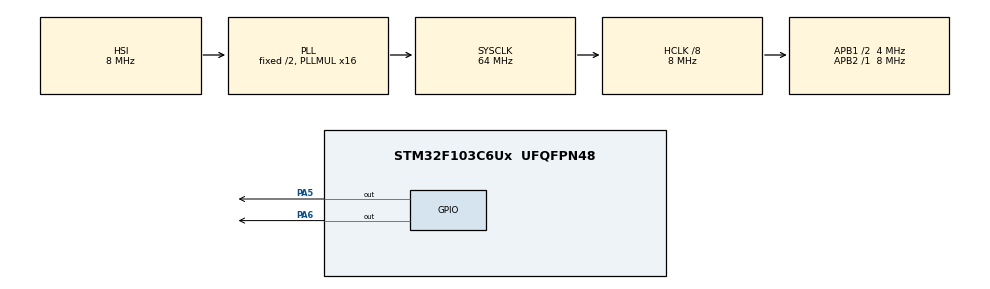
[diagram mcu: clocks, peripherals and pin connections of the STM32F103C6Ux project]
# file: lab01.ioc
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Mcu.Family=STM32F1
Mcu.Name=STM32F103C6Ux
Mcu.Package=UFQFPN48
NVIC.PriorityGroup=NVIC_PRIORITYGROUP_4
PA13.Mode=Serial_Wire
PA13.Signal=SYS_JTMS-SWDIO
PA14.Mode=Serial_Wire
PA14.Signal=SYS_JTCK-SWCLK
PA5.Signal=GPIO_Output
PA6.Signal=GPIO_Output
PC14-OSC32_IN.Mode=LSE-External-Oscillator
PC14-OSC32_IN.Signal=RCC_OSC32_IN
PC15-OSC32_OUT.Mode=LSE-External-Oscillator
PC15-OSC32_OUT.Signal=RCC_OSC32_OUT
PD0-OSC_IN.Mode=HSE-External-Oscillator
PD0-OSC_IN.Signal=RCC_OSC_IN
PD1-OSC_OUT.Mode=HSE-External-Oscillator
PD1-OSC_OUT.Signal=RCC_OSC_OUT
ProjectManager.HeapSize=0x200
ProjectManager.StackSize=0x400
ProjectManager.TargetToolchain=STM32CubeIDE
RCC.AHBCLKDivider=RCC_SYSCLK_DIV8
RCC.AHBFreq_Value=8000000
RCC.APB1CLKDivider=RCC_HCLK_DIV2
RCC.APB1Freq_Value=4000000
RCC.APB1TimFreq_Value=8000000
RCC.APB2Freq_Value=8000000
RCC.APB2TimFreq_Value=8000000
RCC.HCLKFreq_Value=8000000
RCC.PLLMUL=RCC_PLL_MUL16
RCC.SYSCLKFreq_VALUE=64000000
RCC.SYSCLKSource=RCC_SYSCLKSOURCE_PLLCLK
RCC.USBFreq_Value=64000000
board=custom

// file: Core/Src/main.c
/* USER CODE BEGIN Header */
/**
  ******************************************************************************
  * @file           : main.c
  * @brief          : Main program body
  ******************************************************************************
  * @attention
  *
  * Copyright (c) 2024 STMicroelectronics.
  * All rights reserved.
  *
  * This software is licensed under terms that can be found in the LICENSE file
  * in the root directory of this software component.
  * If no LICENSE file comes with this software, it is provided AS-IS.
  *
  ******************************************************************************
  */
/* USER CODE END Header */

#include "main.h"

/* USER CODE BEGIN Includes */
#include <Exercise_01.h>
/* USER CODE END Includes */

void SystemClock_Config(void);
static void MX_GPIO_Init(void);

/* USER CODE BEGIN 0 */
// Định nghĩa thời gian bật/tắt LED
#define RED_LED_ON_TIME 2 // Thời gian bật LED đỏ, đơn vị s
#define RED_LED_OFF_TIME 2 // Thời gian tắt LED đỏ, đơn vị s
#define YELLOW_LED_ON_TIME 2 // Thời gian bật LED vàng, đơn vị s
#define YELLOW_LED_OFF_TIME 2// Thời gian tắt LED vàng, đơn vị s

// Khai báo cấu trúc LED
static led_t red_led = {
    .GPIOx = GPIOA,
    .GPIO_Pin = GPIO_PIN_5,
    .status = LED_OFF,
    .counter = RED_LED_ON_TIME,
    .on_time = RED_LED_ON_TIME,
    .off_time = RED_LED_OFF_TIME
};

static led_t yellow_led = {
    .GPIOx = GPIOA,
    .GPIO_Pin = GPIO_PIN_6,
    .status = LED_ON,
    .counter = YELLOW_LED_OFF_TIME,
    .on_time = YELLOW_LED_ON_TIME,
    .off_time = YELLOW_LED_OFF_TIME
};
/* USER CODE END 0 */

int main(void)
{

  /* MCU Configuration--------------------------------------------------------*/

  /* Reset of all peripherals, Initializes the Flash interface and the Systick. */
  HAL_Init();

  /* Configure the system clock */
  SystemClock_Config();

  /* Initialize all configured peripherals */
  MX_GPIO_Init();
  /* USER CODE BEGIN 2 */
 /* static led_status_t red_led_status = LED_ON;
      static int red_led_counter = ON_TIME;
      static led_status_t yellow_led_status = LED_OFF;
      static int yellow_led_counter = OFF_TIME;
      */

  /* USER CODE END 2 */

  /* Infinite loop */
  while (1)
  {

	  led_run(&red_led);
	  led_run(&yellow_led);
	   HAL_Delay(1000);

  }
}

void SystemClock_Config(void)
{
  RCC_OscInitTypeDef RCC_OscInitStruct = {0};
  RCC_ClkInitTypeDef RCC_ClkInitStruct = {0};

  /** Initializes the RCC Oscillators according to the specified parameters
  * in the RCC_OscInitTypeDef structure.
  */
  RCC_OscInitStruct.OscillatorType = RCC_OSCILLATORTYPE_HSI;
  RCC_OscInitStruct.HSIState = RCC_HSI_ON;
  RCC_OscInitStruct.HSICalibrationValue = RCC_HSICALIBRATION_DEFAULT;
  RCC_OscInitStruct.PLL.PLLState = RCC_PLL_ON;
  RCC_OscInitStruct.PLL.PLLSource = RCC_PLLSOURCE_HSI_DIV2;
  RCC_OscInitStruct.PLL.PLLMUL = RCC_PLL_MUL16;
  if (HAL_RCC_OscConfig(&RCC_OscInitStruct) != HAL_OK)
  {
    Error_Handler();
  }

  /** Initializes the CPU, AHB and APB buses clocks
  */
  RCC_ClkInitStruct.ClockType = RCC_CLOCKTYPE_HCLK|RCC_CLOCKTYPE_SYSCLK
                              |RCC_CLOCKTYPE_PCLK1|RCC_CLOCKTYPE_PCLK2;
  RCC_ClkInitStruct.SYSCLKSource = RCC_SYSCLKSOURCE_PLLCLK;
  RCC_ClkInitStruct.AHBCLKDivider = RCC_SYSCLK_DIV8;
  RCC_ClkInitStruct.APB1CLKDivider = RCC_HCLK_DIV2;
  RCC_ClkInitStruct.APB2CLKDivider = RCC_HCLK_DIV1;

  if (HAL_RCC_ClockConfig(&RCC_ClkInitStruct, FLASH_LATENCY_2) != HAL_OK)
  {
    Error_Handler();
  }
}

static void MX_GPIO_Init(void)
{
  GPIO_InitTypeDef GPIO_InitStruct = {0};

  /* GPIO Ports Clock Enable */
  __HAL_RCC_GPIOC_CLK_ENABLE();
  __HAL_RCC_GPIOD_CLK_ENABLE();
  __HAL_RCC_GPIOA_CLK_ENABLE();

  /*Configure GPIO pin Output Level */
  HAL_GPIO_WritePin(GPIOA, GPIO_PIN_5|GPIO_PIN_6, GPIO_PIN_RESET);

  /*Configure GPIO pins : PA5 PA6 */
  GPIO_InitStruct.Pin = GPIO_PIN_5|GPIO_PIN_6;
  GPIO_InitStruct.Mode = GPIO_MODE_OUTPUT_PP;
  GPIO_InitStruct.Pull = GPIO_NOPULL;
  GPIO_InitStruct.Speed = GPIO_SPEED_FREQ_LOW;
  HAL_GPIO_Init(GPIOA, &GPIO_InitStruct);

}

void Error_Handler(void)
{
  __disable_irq();
  while (1)
  {
  }
}
